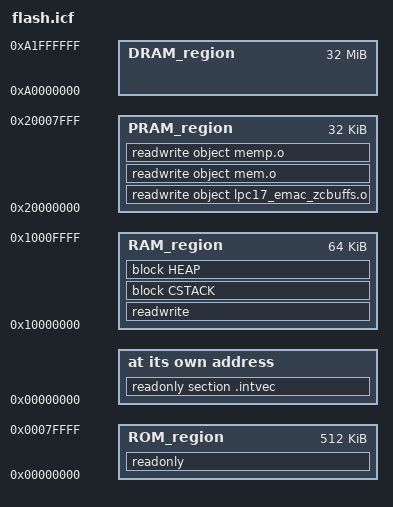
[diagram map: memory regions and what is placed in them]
/*###ICF### Section handled by ICF editor, don't touch! ****/
/*-Editor annotation file-*/
/* IcfEditorFile="$TOOLKIT_DIR$\config\ide\IcfEditor\cortex_v1_0.xml" */
/*-Specials-*/
define symbol __ICFEDIT_intvec_start__ = 0x00000000;
/*-Memory Regions-*/
define symbol __ICFEDIT_region_ROM_start__ = 0x00000000;
define symbol __ICFEDIT_region_ROM_end__   = 0x0007FFFF;
define symbol __ICFEDIT_region_RAM_start__ = 0x10000000;
define symbol __ICFEDIT_region_RAM_end__   = 0x1000FFFF;
/*-Sizes-*/
define symbol __ICFEDIT_size_cstack__ = 0x400;
define symbol __ICFEDIT_size_heap__   = 0x400;
/**** End of ICF editor section. ###ICF###*/


define memory mem with size = 4G;
define region ROM_region   = mem:[from __ICFEDIT_region_ROM_start__   to __ICFEDIT_region_ROM_end__];
define region RAM_region   = mem:[from __ICFEDIT_region_RAM_start__   to __ICFEDIT_region_RAM_end__];
define region PRAM_region  = mem:[from 0x20000000   to 0x20007FFF];
define region DRAM_region  = mem:[from 0xA0000000   to 0xA1FFFFFF];

define block CSTACK    with alignment = 8, size = __ICFEDIT_size_cstack__   { };
define block HEAP      with alignment = 8, size = __ICFEDIT_size_heap__     { };

initialize by copy { readwrite };
//initialize by copy with packing = none { section __DLIB_PERTHREAD }; // Required in a multi-threaded application
do not initialize  { section .noinit };

place at address mem:__ICFEDIT_intvec_start__ { readonly section .intvec };

place in ROM_region   { readonly };
place in RAM_region   { readwrite,
                        block CSTACK, block HEAP };
place in PRAM_region  { readwrite object lpc17_emac_zcbuffs.o, readwrite object mem.o,
                        readwrite object memp.o };
